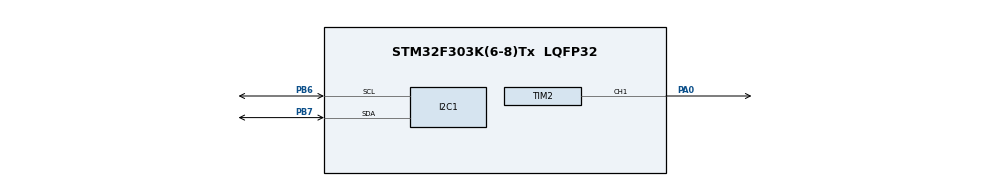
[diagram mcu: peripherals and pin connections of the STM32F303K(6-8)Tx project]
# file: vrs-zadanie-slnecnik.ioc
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I2C1.OwnAddress=1
Mcu.Family=STM32F3
Mcu.Name=STM32F303K(6-8)Tx
Mcu.Package=LQFP32
NVIC.I2C1_EV_IRQn=true\:0\:0\:false\:false\:true\:true\:true\:true
NVIC.PriorityGroup=NVIC_PRIORITYGROUP_4
PA0.Signal=S_TIM2_CH1_ETR
PA13.Mode=Serial_Wire
PA13.Signal=SYS_JTMS-SWDIO
PA14.Mode=Serial_Wire
PA14.Signal=SYS_JTCK-SWCLK
PB6.GPIO_Pu=GPIO_PULLUP
PB6.Mode=I2C
PB6.Signal=I2C1_SCL
PB7.GPIO_Pu=GPIO_PULLUP
PB7.Mode=I2C
PB7.Signal=I2C1_SDA
ProjectManager.HeapSize=0x200
ProjectManager.StackSize=0x400
ProjectManager.TargetToolchain=STM32CubeIDE
RCC.AHBFreq_Value=8000000
RCC.APB1Freq_Value=8000000
RCC.APB2Freq_Value=8000000
RCC.CortexFreq_Value=8000000
RCC.HSE_VALUE=8000000
RCC.HSI_VALUE=8000000
RCC.SYSCLKFreq_VALUE=8000000
SH.S_TIM2_CH1_ETR.0=TIM2_CH1,PWM Generation1 CH1
TIM2.Channel-PWM\ Generation1\ CH1=TIM_CHANNEL_1
TIM2.Period=9999
TIM2.Prescaler=15
VP_TIM2_VS_ClockSourceINT.Mode=Internal
board=custom

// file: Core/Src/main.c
/* USER CODE BEGIN Header */
/**
 ******************************************************************************
 * @file           : main.c
 * @brief          : Main program body
 ******************************************************************************
 * @attention
 *
 * Copyright (c) 2022 STMicroelectronics.
 * All rights reserved.
 *
 * This software is licensed under terms that can be found in the LICENSE file
 * in the root directory of this software component.
 * If no LICENSE file comes with this software, it is provided AS-IS.
 *
 ******************************************************************************
 */
/* USER CODE END Header */
#include "main.h"
#include "i2c.h"
#include "tim.h"
#include "gpio.h"

/* USER CODE BEGIN Includes */
#include "stdio.h"
#include "string.h"
#include "vd6283tx.h"
/* USER CODE END Includes */

/* USER CODE BEGIN PV */

uint8_t Mode = 1;
uint8_t EnginePosition = 0;
int data;
int angle = 0;

// USART_TypeDef huart1;
/* USER CODE END PV */

void SystemClock_Config(void);
/* USER CODE BEGIN PFP */
void MX_GPIO_Init(void);
void MX_TIM2_Init(void);
void servoRotateToPosition(int angle);
uint8_t Light_Scanner(uint8_t mode_of_scanning, uint8_t engine_position);
/* USER CODE END PFP */

int main(void)
{

  /* MCU Configuration--------------------------------------------------------*/

  /* Reset of all peripherals, Initializes the Flash interface and the Systick. */
  HAL_Init();

  /* Configure the system clock */
  SystemClock_Config();

  /* Initialize all configured peripherals */
  MX_GPIO_Init();
  MX_TIM2_Init();
  MX_I2C1_Init();
  /* USER CODE BEGIN 2 */
  HAL_TIM_PWM_Start(&htim2, TIM_CHANNEL_1);
  /* USER CODE END 2 */

  /* Infinite loop */
  /* USER CODE BEGIN WHILE */
  while (1)
  {
    EnginePosition = Light_Scanner(Mode, EnginePosition); // Obtaining position for engine to be move to.
    servoRotateToPosition(EnginePosition); // Setting engine to required position.
    Mode = 2; // Changing mode to 2 after initial global measuring.
    LL_mDelay(15000); // Wait time between measurements 15 seconds.

    /* USER CODE END WHILE */

  }
}

void SystemClock_Config(void)
{
  LL_FLASH_SetLatency(LL_FLASH_LATENCY_0);
  while(LL_FLASH_GetLatency()!= LL_FLASH_LATENCY_0)
  {
  }
  LL_RCC_HSI_Enable();

   /* Wait till HSI is ready */
  while(LL_RCC_HSI_IsReady() != 1)
  {

  }
  LL_RCC_HSI_SetCalibTrimming(16);
  LL_RCC_SetAHBPrescaler(LL_RCC_SYSCLK_DIV_1);
  LL_RCC_SetAPB1Prescaler(LL_RCC_APB1_DIV_1);
  LL_RCC_SetAPB2Prescaler(LL_RCC_APB2_DIV_1);
  LL_RCC_SetSysClkSource(LL_RCC_SYS_CLKSOURCE_HSI);

   /* Wait till System clock is ready */
  while(LL_RCC_GetSysClkSource() != LL_RCC_SYS_CLKSOURCE_STATUS_HSI)
  {

  }
  LL_SetSystemCoreClock(8000000);

   /* Update the time base */
  if (HAL_InitTick (TICK_INT_PRIORITY) != HAL_OK)
  {
    Error_Handler();
  }
  LL_RCC_SetI2CClockSource(LL_RCC_I2C1_CLKSOURCE_HSI);
}

/* USER CODE BEGIN 4 */
/*
 */

/**
 * @brief Light intensity scanning Function
 * @param uint8_t mode_of_scanning (type of scanning procedure 1 = full scan, 2 = short scan for adjustment of position),
 *     	uint8_t engine_position	(current position of the engine in degrees)
 * @retval uint8_t position of strongest light intensity
 */

uint8_t Light_Scanner(uint8_t mode_of_scanning, uint8_t engine_position)
{

  int light_intensity = 0;
  uint8_t light_intensity_position = 0;
  int measured_light = 0;

  if (mode_of_scanning == 1)
  {
    angle = 0;
    for (int degree = 0; degree <= 180; degree = degree + 5)
    {
      servoRotateToPosition(degree);
	  vd6283tx_init();
	  measured_light = vd6283tx_get_als_ch2();

      if (light_intensity < measured_light) // Saving position with highest measured light intensity.
      {
        light_intensity = measured_light;
        light_intensity_position = degree;
        angle = degree;
      }
    }

    return light_intensity_position;
  }
  else if (mode_of_scanning == 2)
  {
    if (engine_position < 5) // Condition for engine to not move below set minimum 0 degrees.
    {
      angle = 0; // Measuring light intensity at 0 degrees
      servoRotateToPosition(angle);
      vd6283tx_init();
	  measured_light = vd6283tx_get_als_ch2();

      light_intensity = measured_light;
      light_intensity_position = 0;

      angle = angle + 5; // Measuring light intensity at 5 degrees
      servoRotateToPosition(angle);
      vd6283tx_init();
	  measured_light = vd6283tx_get_als_ch2();

	  if (light_intensity < measured_light)
	  {
		  light_intensity = measured_light;
		  light_intensity_position = angle;
	  }

      return light_intensity_position;
    }
    else if (angle > 180) // Condition for engine to not move above set maximum 180 degrees.
    {
      angle = 180; // Measuring light intensity at 180 degrees
      servoRotateToPosition(angle);

      vd6283tx_init();
	  measured_light = vd6283tx_get_als_ch2();
	  light_intensity = measured_light;
	  light_intensity_position = angle;

      angle = angle - 5; // Measuring light intensity at 175 degrees
      servoRotateToPosition(angle);
      vd6283tx_init();
	  measured_light = vd6283tx_get_als_ch2();

      if (light_intensity < measured_light)
      {
        light_intensity = measured_light;
        light_intensity_position = angle;
      }

      return light_intensity_position;
    }
    else // Condition for engine to be able to move in between 0 - 180 degrees.
    {
      angle = angle - 5; // Measuring light intensity 5 degrees back.
      servoRotateToPosition(angle);
      vd6283tx_init();
	  measured_light = vd6283tx_get_als_ch2();

      light_intensity = measured_light;
      light_intensity_position = angle;

      angle = angle + 5; // Measuring light intensity at original degrees
      servoRotateToPosition(angle);
      vd6283tx_init();
	  measured_light = vd6283tx_get_als_ch2();

      if (light_intensity < measured_light)
      {
        light_intensity = measured_light;
        light_intensity_position = angle;
      }

      angle = angle + 5; // Measuring light intensity 5 degrees forward.
      servoRotateToPosition(angle);
	  vd6283tx_init();
	  measured_light = vd6283tx_get_als_ch2();

	  if (light_intensity < measured_light)
	  {
		  light_intensity = measured_light;
		  light_intensity_position = angle;
	  }

      return light_intensity_position;
    }
  }
  else // If parameter mode_of_scanning haven't accepted values 1 or 2 position of engine stay unchanged.
  {
    return engine_position;
  }
}

/**
 * @brief Takes the requested angle value, and rotates the servo motor to the desired rotation.
 * If the angle is below 0 then we rotate the servo motor to the 0 degre position. If the angle is
 * above 180 degree, then  we set the servo motor rotation position to 180 degree, else the angle
 * value will be multiplied by 5.5555 and we will add 180 to the final value.
 * We received the multiplier value from this equation ((1180-180)/180)/servo motor macimum angle reach.
 * we add 180 to the final value, because the servo motor starts rotate from pulse value 180.
 *
 * @param angle The requested angle in degrees.
 */
void servoRotateToPosition(int angle)
{
  if (angle < 0)
  {
    __HAL_TIM_SET_COMPARE(&htim2, TIM_CHANNEL_1, 180);
  }
  else if (angle == 0)
  {
    __HAL_TIM_SET_COMPARE(&htim2, TIM_CHANNEL_1, 180); // 0deg
  }
  else if (angle > 0 && angle <= 180)
  {
    __HAL_TIM_SET_COMPARE(&htim2, TIM_CHANNEL_1, angle * 5.5555 + 180);
  }
  else
  {
    __HAL_TIM_SET_COMPARE(&htim2, TIM_CHANNEL_1, 1180);
  }
}

/* USER CODE END 4 */

void Error_Handler(void)
{
  __disable_irq();
  while (1)
  {
  }
}
